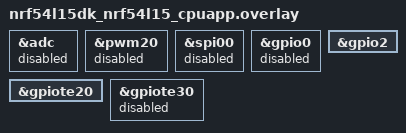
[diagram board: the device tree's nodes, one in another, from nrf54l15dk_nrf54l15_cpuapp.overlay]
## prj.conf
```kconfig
CONFIG_GPIO=y
CONFIG_PM_DEVICE=y
```

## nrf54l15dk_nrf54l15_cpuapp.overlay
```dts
// To get started, press Ctrl+Space to bring up the completion menu and view the available nodes.

// You can also use the buttons in the sidebar to perform actions on nodes.
// Actions currently available include:

// * Enabling / disabling the node
// * Adding the bus to a bus
// * Removing the node
// * Connecting ADC channels

// For more help, browse the DeviceTree documentation at https://docs.zephyrproject.org/latest/guides/dts/index.html
// You can also visit the nRF DeviceTree extension documentation at https://docs.nordicsemi.com/bundle/nrf-connect-vscode/page/guides/ncs_configure_app.html#devicetree-support-in-the-extension

&adc {
	status = "disabled";
};

&pwm20 {
	status = "disabled";
};

&spi00 {
	status = "disabled";
};

&gpio0 {
	status = "disabled";
};

&gpiote20 {
	status = "okay";
};

&gpiote30 {
	status = "disabled";
};

&gpio2 {
	status = "okay";
};
```

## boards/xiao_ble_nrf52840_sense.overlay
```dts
// To get started, press Ctrl+Space to bring up the completion menu and view the available nodes.

// You can also use the buttons in the sidebar to perform actions on nodes.
// Actions currently available include:

// * Enabling / disabling the node
// * Adding the bus to a bus
// * Removing the node
// * Connecting ADC channels

// For more help, browse the DeviceTree documentation at https://docs.zephyrproject.org/latest/guides/dts/index.html
// You can also visit the nRF DeviceTree extension documentation at https://docs.nordicsemi.com/bundle/nrf-connect-vscode/page/guides/ncs_configure_app.html#devicetree-support-in-the-extension

/ {
	buttons {
		compatible = "gpio-keys";
		sw0: sw0 {
			gpios = <&gpio0 2 GPIO_ACTIVE_HIGH>;
			label = "Switch 0";
		};
	};

	aliases {
		sw0 = &sw0;
	};
};
```

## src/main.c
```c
/*
 * Copyright (c) 2022 Joao Dullius
 *
 * SPDX-License-Identifier: Apache-2.0
 */

 #include <zephyr/kernel.h>
 #include <zephyr/drivers/gpio.h>
 #include <zephyr/pm/device.h>
 
 #define LED0_NODE   DT_ALIAS(led0)
 #define BUTTON_NODE DT_ALIAS(sw0)
 
 static const struct gpio_dt_spec led = GPIO_DT_SPEC_GET(LED0_NODE, gpios);
 static const struct gpio_dt_spec button = GPIO_DT_SPEC_GET(BUTTON_NODE, gpios);

 static const struct device *uart_console = DEVICE_DT_GET(DT_CHOSEN(zephyr_console));
 static bool uart_active = true;
 
 static struct gpio_callback button_cb_data;
 
 void button_pressed_isr(const struct device *dev, struct gpio_callback *cb, uint32_t pins)
 {
    gpio_pin_toggle_dt(&led);
    printk("Button pressed!\n");

    pm_device_action_run(uart_console, uart_active ? PM_DEVICE_ACTION_SUSPEND : PM_DEVICE_ACTION_RESUME);
    uart_active = !uart_active;
 }
 
 int main(void)
 {
     int ret;
 
     printk("Hello Button + LED (Interrupt)!\n");
 
     if (!device_is_ready(led.port) || !device_is_ready(button.port)) {
         return -1;
     }
 
     ret = gpio_pin_configure_dt(&led, GPIO_OUTPUT_INACTIVE);
     if (ret < 0) {
         return -1;
     }
 
     ret = gpio_pin_configure_dt(&button, GPIO_INPUT);
     if (ret < 0) {
         return -1;
     }
 
     ret = gpio_pin_interrupt_configure_dt(&button, GPIO_INT_EDGE_TO_ACTIVE);
     if (ret < 0) {
         return -1;
     }
 
     gpio_init_callback(&button_cb_data, button_pressed_isr, BIT(button.pin));
     gpio_add_callback(button.port, &button_cb_data);
 
     while (1) {
         k_sleep(K_FOREVER);
     }
 }
 
```
